# ATxmega256A3BU device description
Architecture: AVR8_XMEGA; Family: AVR XMEGA
Registers are 8-bit, access not given, no defined reset value unless marked. A register's access mark holds for its fields unless they carry their own. Offsets are from the block's base; [hi:lo] are bit positions; {n}, {i} and the like mark numbered series; 'fields as' and 'values as' point back to an identical list.

## EVSYS — Event System
Instances: EVSYS 0x0180
{0x0+i} CH{i}MUX (i=0..7) — Event Channel {i} Multiplexer
  [7:0] CHMUX
    0=OFF; 8=RTC_OVF (RTC Overflow); 9=RTC_CMP (RTC Compare Match); 10=USB (USB Setup, SOF, CRC error and UNF/OVF); 16=ACA_CH0 (Analog Comparator A Channel 0); 17=ACA_CH1 (Analog Comparator A Channel 1); 18=ACA_WIN (Analog Comparator A Window); 19=ACB_CH0 (Analog Comparator B Channel 0); 20=ACB_CH1 (Analog Comparator B Channel 1); 21=ACB_WIN (Analog Comparator B Window); {v}=ADCA_CH{v-32} (ADC A Channel {v-32}) (v=32..35); {v}=ADCB_CH{v-36} (ADC B Channel {v-36}) (v=36..39); {v}=PORTA_PIN{v-80} (v=80..87); {v}=PORTB_PIN{v-88} (v=88..95); {v}=PORTC_PIN{v-96} (v=96..103); {v}=PORTD_PIN{v-104} (v=104..111); {v}=PORTE_PIN{v-112} (v=112..119); {v}=PORTF_PIN{v-120} (v=120..127); 128=PRESCALER_1 (Prescaler, divide by 1); 129=PRESCALER_2 (Prescaler, divide by 2); 130=PRESCALER_4 (Prescaler, divide by 4); 131=PRESCALER_8 (Prescaler, divide by 8); 132=PRESCALER_16 (Prescaler, divide by 16); 133=PRESCALER_32 (Prescaler, divide by 32); 134=PRESCALER_64 (Prescaler, divide by 64); 135=PRESCALER_128 (Prescaler, divide by 128); 136=PRESCALER_256 (Prescaler, divide by 256); 137=PRESCALER_512 (Prescaler, divide by 512); 138=PRESCALER_1024 (Prescaler, divide by 1024); 139=PRESCALER_2048 (Prescaler, divide by 2048); 140=PRESCALER_4096 (Prescaler, divide by 4096); 141=PRESCALER_8192 (Prescaler, divide by 8192); 142=PRESCALER_16384 (Prescaler, divide by 16384); 143=PRESCALER_32768 (Prescaler, divide by 32768); 192=TCC0_OVF (Timer/Counter C0 Overflow); 193=TCC0_ERR (Timer/Counter C0 Error); 196=TCC0_CCA (Timer/Counter C0 Compare or Capture A); 197=TCC0_CCB (Timer/Counter C0 Compare or Capture B); 198=TCC0_CCC (Timer/Counter C0 Compare or Capture C); 199=TCC0_CCD (Timer/Counter C0 Compare or Capture D); 200=TCC1_OVF (Timer/Counter C1 Overflow); 201=TCC1_ERR (Timer/Counter C1 Error); 204=TCC1_CCA (Timer/Counter C1 Compare or Capture A); 205=TCC1_CCB (Timer/Counter C1 Compare or Capture B); 208=TCD0_OVF (Timer/Counter D0 Overflow); 209=TCD0_ERR (Timer/Counter D0 Error); 212=TCD0_CCA (Timer/Counter D0 Compare or Capture A); 213=TCD0_CCB (Timer/Counter D0 Compare or Capture B); 214=TCD0_CCC (Timer/Counter D0 Compare or Capture C); 215=TCD0_CCD (Timer/Counter D0 Compare or Capture D); 216=TCD1_OVF (Timer/Counter D1 Overflow); 217=TCD1_ERR (Timer/Counter D1 Error); 220=TCD1_CCA (Timer/Counter D1 Compare or Capture A); 221=TCD1_CCB (Timer/Counter D1 Compare or Capture B); 224=TCE0_OVF (Timer/Counter E0 Overflow); 225=TCE0_ERR (Timer/Counter E0 Error); 228=TCE0_CCA (Timer/Counter E0 Compare or Capture A); 229=TCE0_CCB (Timer/Counter E0 Compare or Capture B); 230=TCE0_CCC (Timer/Counter E0 Compare or Capture C); 231=TCE0_CCD (Timer/Counter E0 Compare or Capture D); 232=TCE1_OVF (Timer/Counter E1 Overflow); 233=TCE1_ERR (Timer/Counter E1 Error); 236=TCE1_CCA (Timer/Counter E1 Compare or Capture A); 237=TCE1_CCB (Timer/Counter E1 Compare or Capture B); 240=TCF0_OVF (Timer/Counter F0 Overflow); 241=TCF0_ERR (Timer/Counter F0 Error); 244=TCF0_CCA (Timer/Counter F0 Compare or Capture A); 245=TCF0_CCB (Timer/Counter F0 Compare or Capture B); 246=TCF0_CCC (Timer/Counter F0 Compare or Capture C); 247=TCF0_CCD (Timer/Counter F0 Compare or Capture D); 248=TCF1_OVF (Timer/Counter F1 Overflow); 249=TCF1_ERR (Timer/Counter F1 Error); 252=TCF1_CCA (Timer/Counter F1 Compare or Capture A); 253=TCF1_CCB (Timer/Counter F1 Compare or Capture B)
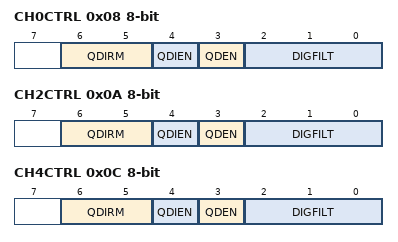
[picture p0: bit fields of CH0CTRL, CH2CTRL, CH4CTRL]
0x08 CH0CTRL — Channel 0 Control Register
  [6:5] QDIRM — Quadrature Decoder Index Recognition Mode
  [4] QDIEN — Quadrature Decoder Index Enable
  [3] QDEN — Quadrature Decoder Enable
  [2:0] DIGFILT — Digital Filter
    0=1SAMPLE; {v}={v+1}SAMPLES (v=1..7)
0x09 CH1CTRL — Channel 1 Control Register
  [2:0] DIGFILT — Digital Filter
    0=1SAMPLE; {v}={v+1}SAMPLES (v=1..7)
0x0A CH2CTRL — Channel 2 Control Register
  [6:5] QDIRM — Quadrature Decoder Index Recognition Mode
    0=QDPH0 = 0, QDPH90 = 0; 1=QDPH0 = 0, QDPH90 = 1; 2=QDPH0 = 1, QDPH90 = 0; 3=QDPH0 = 1, QDPH90 = 1
  [4] QDIEN — Quadrature Decoder Index Enable
  [3] QDEN — Quadrature Decoder Enable
  [2:0] DIGFILT — Digital Filter
    0=1SAMPLE; {v}={v+1}SAMPLES (v=1..7)
0x0B CH3CTRL — Channel 3 Control Register
  fields as CH1CTRL
0x0C CH4CTRL — Channel 4 Control Register
  fields as CH2CTRL
{0x8+i} CH{i}CTRL (i=5..7) — Channel {i} Control Register
  fields as CH1CTRL
0x10 STROBE — Event Strobe
0x11 DATA — Event Data
